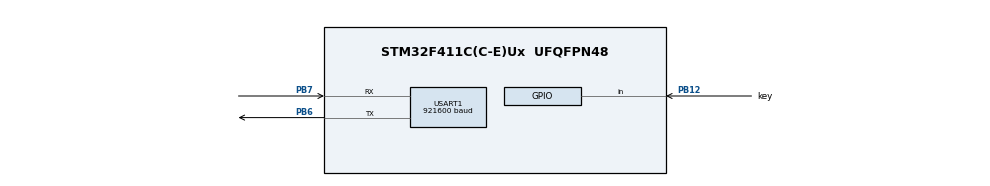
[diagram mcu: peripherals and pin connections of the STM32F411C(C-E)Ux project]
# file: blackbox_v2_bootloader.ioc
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Mcu.Family=STM32F4
Mcu.Name=STM32F411C(C-E)Ux
Mcu.Package=UFQFPN48
NVIC.PriorityGroup=NVIC_PRIORITYGROUP_4
NVIC.RCC_IRQn=true\:0\:0\:false\:false\:true\:true\:false\:true
NVIC.USART1_IRQn=true\:0\:0\:false\:false\:true\:true\:true\:true
PA13.Mode=Serial_Wire
PA13.Signal=SYS_JTMS-SWDIO
PA14.Mode=Serial_Wire
PA14.Signal=SYS_JTCK-SWCLK
PB12.GPIO_Label=key
PB12.GPIO_PuPd=GPIO_PULLDOWN
PB12.Signal=GPIO_Input
PB6.Mode=Asynchronous
PB6.Signal=USART1_TX
PB7.Mode=Asynchronous
PB7.Signal=USART1_RX
PH0\ -\ OSC_IN.Mode=HSE-External-Oscillator
PH0\ -\ OSC_IN.Signal=RCC_OSC_IN
PH1\ -\ OSC_OUT.Mode=HSE-External-Oscillator
PH1\ -\ OSC_OUT.Signal=RCC_OSC_OUT
ProjectManager.HeapSize=0x200
ProjectManager.StackSize=0x1400
ProjectManager.TargetToolchain=CMake
RCC.48MHZClocksFreq_Value=48000000.00000001
RCC.AHBFreq_Value=96000000.00000001
RCC.APB1CLKDivider=RCC_HCLK_DIV2
RCC.APB1Freq_Value=48000000.00000001
RCC.APB1TimFreq_Value=96000000.00000001
RCC.APB2Freq_Value=96000000.00000001
RCC.APB2TimFreq_Value=96000000.00000001
RCC.CortexFreq_Value=96000000.00000001
RCC.HCLKFreq_Value=96000000.00000001
RCC.HSE_VALUE=8000000
RCC.HSI_VALUE=16000000
RCC.LSE_VALUE=32768
RCC.PLLM=7
RCC.PLLN=336
RCC.PLLP=RCC_PLLP_DIV4
RCC.PLLQ=8
RCC.PLLSourceVirtual=RCC_PLLSOURCE_HSE
RCC.SYSCLKFreq_VALUE=96000000.00000001
RCC.SYSCLKSource=RCC_SYSCLKSOURCE_PLLCLK
RCC.VCOOutputFreq_Value=384000000.00000006
USART1.BaudRate=921600
USART1.VirtualMode=VM_ASYNC
board=custom

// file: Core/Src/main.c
/* USER CODE BEGIN Header */
/**
  ******************************************************************************
  * @file           : main.c
  * @brief          : Main program body
  ******************************************************************************
  * @attention
  *
  * Copyright (c) 2026 STMicroelectronics.
  * All rights reserved.
  *
  * This software is licensed under terms that can be found in the LICENSE file
  * in the root directory of this software component.
  * If no LICENSE file comes with this software, it is provided AS-IS.
  *
  ******************************************************************************
  */
/* USER CODE END Header */
#include "main.h"
#include "usart.h"
#include "gpio.h"

/* USER CODE BEGIN Includes */
#include "ringbuff.h"
#include "fh_bootloader.h"
#include "fh_stream.h"
#include "fh_sw_crc.h"
/* USER CODE END Includes */

/* USER CODE BEGIN PV */
extern uint8_t rxbuf_u1;
/* USER CODE END PV */

void SystemClock_Config(void);

int main(void)
{

  /* MCU Configuration--------------------------------------------------------*/

  /* Reset of all peripherals, Initializes the Flash interface and the Systick. */
  HAL_Init();

  /* Configure the system clock */
  SystemClock_Config();

  /* Initialize all configured peripherals */
  MX_GPIO_Init();
  MX_USART1_UART_Init();
  /* USER CODE BEGIN 2 */
  fh_stream_set_crc_func(fh_sw_crc32);
  RingBuff_Init(&Uart1_RingBuff);
  HAL_UART_Receive_IT(&huart1, &rxbuf_u1, 1);
  fh_bl_boot();
  /* USER CODE END 2 */

  /* Infinite loop */
  while (1)
  {

  }
}

void SystemClock_Config(void)
{
  LL_FLASH_SetLatency(LL_FLASH_LATENCY_3);
  while(LL_FLASH_GetLatency()!= LL_FLASH_LATENCY_3)
  {
  }
  LL_PWR_SetRegulVoltageScaling(LL_PWR_REGU_VOLTAGE_SCALE1);
  LL_RCC_HSE_Enable();

   /* Wait till HSE is ready */
  while(LL_RCC_HSE_IsReady() != 1)
  {

  }
  LL_RCC_PLL_ConfigDomain_SYS(LL_RCC_PLLSOURCE_HSE, LL_RCC_PLLM_DIV_7, 336, LL_RCC_PLLP_DIV_4);
  LL_RCC_PLL_Enable();

   /* Wait till PLL is ready */
  while(LL_RCC_PLL_IsReady() != 1)
  {

  }
  while (LL_PWR_IsActiveFlag_VOS() == 0)
  {
  }
  LL_RCC_SetAHBPrescaler(LL_RCC_SYSCLK_DIV_1);
  LL_RCC_SetAPB1Prescaler(LL_RCC_APB1_DIV_2);
  LL_RCC_SetAPB2Prescaler(LL_RCC_APB2_DIV_1);
  LL_RCC_SetSysClkSource(LL_RCC_SYS_CLKSOURCE_PLL);

   /* Wait till System clock is ready */
  while(LL_RCC_GetSysClkSource() != LL_RCC_SYS_CLKSOURCE_STATUS_PLL)
  {

  }
  LL_SetSystemCoreClock(96000000);

   /* Update the time base */
  if (HAL_InitTick (TICK_INT_PRIORITY) != HAL_OK)
  {
    Error_Handler();
  }
  LL_RCC_SetTIMPrescaler(LL_RCC_TIM_PRESCALER_TWICE);
}

void Error_Handler(void)
{
  __disable_irq();
  while (1)
  {
  }
}
